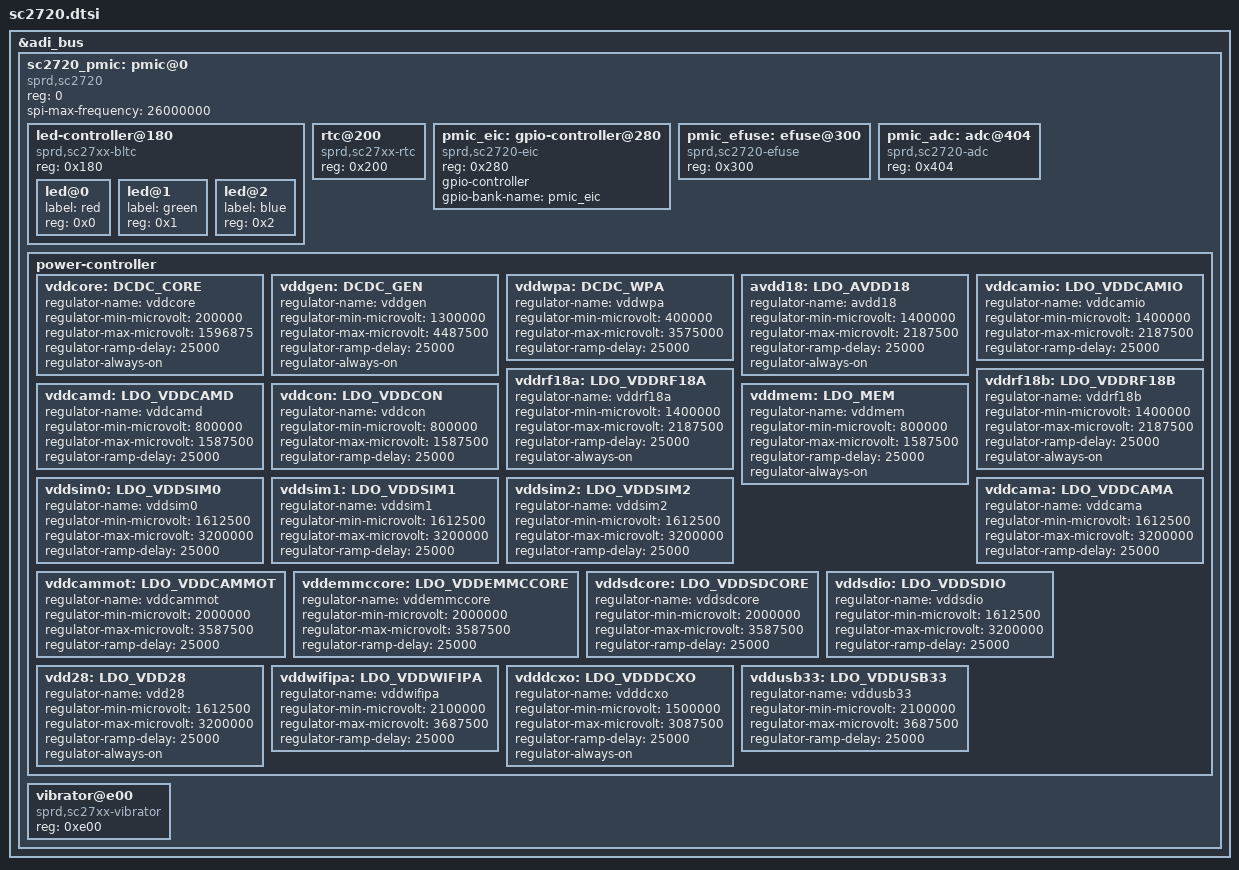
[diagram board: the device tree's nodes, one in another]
/*
 * Spreadtrum Analog Die SC2720 DTS file
 *
 * Copyright (C) 2019, Spreadtrum Communications Inc.
 *
 * This file is licensed under a dual GPLv2 or X11 license.
 */

&adi_bus {
	sc2720_pmic: pmic@0 {
		compatible = "sprd,sc2720";
		reg = <0>;
		spi-max-frequency = <26000000>;
		#address-cells = <1>;
		#size-cells = <0>;

		led-controller@180 {
			compatible = "sprd,sc27xx-bltc", "sprd,sc2721-bltc", "sprd,sc2720-bltc";
			#address-cells = <1>;
			#size-cells = <0>;
			reg = <0x180>;

			led@0 {
				label = "red";
				reg = <0x0>;
			};

			led@1 {
				label = "green";
				reg = <0x1>;
			};

			led@2 {
				label = "blue";
				reg = <0x2>;
			};
		};

		rtc@200 {
			compatible = "sprd,sc27xx-rtc";
			reg = <0x200>;
		};

		pmic_eic: gpio-controller@280 {
			compatible = "sprd,sc2720-eic", "sprd,sc2731-eic";
			reg = <0x280>;
			gpio-controller;
			gpio-bank-name = "pmic_eic";
			#gpio-cells = <2>;
		};

		pmic_efuse: efuse@300 {
			compatible = "sprd,sc2720-efuse";
			reg = <0x300>;
		};

		pmic_adc: adc@404 {
			compatible ="sprd,sc2720-adc";
			reg = <0x404>;
		};

		power-controller {
			vddcore: DCDC_CORE {
				regulator-name = "vddcore";
				regulator-min-microvolt = <200000>;
				regulator-max-microvolt = <1596875>;
				regulator-ramp-delay = <25000>;
				regulator-always-on;
			};

			vddgen: DCDC_GEN {
				regulator-name = "vddgen";
				regulator-min-microvolt = <1300000>;
				regulator-max-microvolt = <4487500>;
				regulator-ramp-delay = <25000>;
				regulator-always-on;
			};

			vddwpa: DCDC_WPA {
				regulator-name = "vddwpa";
				regulator-min-microvolt = <400000>;
				regulator-max-microvolt = <3575000>;
				regulator-ramp-delay = <25000>;
			};

			avdd18: LDO_AVDD18 {
				regulator-name = "avdd18";
				regulator-min-microvolt = <1400000>;
				regulator-max-microvolt = <2187500>;
				regulator-ramp-delay = <25000>;
				regulator-always-on;
			};

			vddcamio: LDO_VDDCAMIO {
				regulator-name = "vddcamio";
				regulator-min-microvolt = <1400000>;
				regulator-max-microvolt = <2187500>;
				regulator-ramp-delay = <25000>;
			};

			vddrf18a: LDO_VDDRF18A {
				regulator-name = "vddrf18a";
				regulator-min-microvolt = <1400000>;
				regulator-max-microvolt = <2187500>;
				regulator-ramp-delay = <25000>;
				regulator-always-on;
			};

			vddrf18b: LDO_VDDRF18B {
				regulator-name = "vddrf18b";
				regulator-min-microvolt = <1400000>;
				regulator-max-microvolt = <2187500>;
				regulator-ramp-delay = <25000>;
				regulator-always-on;
			};

			vddcamd: LDO_VDDCAMD {
				regulator-name = "vddcamd";
				regulator-min-microvolt = <800000>;
				regulator-max-microvolt = <1587500>;
				regulator-ramp-delay = <25000>;
			};

			vddcon: LDO_VDDCON {
				regulator-name = "vddcon";
				regulator-min-microvolt = <800000>;
				regulator-max-microvolt = <1587500>;
				regulator-ramp-delay = <25000>;
			};

			vddmem: LDO_MEM {
				regulator-name = "vddmem";
				regulator-min-microvolt = <800000>;
				regulator-max-microvolt = <1587500>;
				regulator-ramp-delay = <25000>;
				regulator-always-on;
			};

			vddsim0: LDO_VDDSIM0 {
				regulator-name = "vddsim0";
				regulator-min-microvolt = <1612500>;
				regulator-max-microvolt = <3200000>;
				regulator-ramp-delay = <25000>;
			};

			vddsim1: LDO_VDDSIM1 {
				regulator-name = "vddsim1";
				regulator-min-microvolt = <1612500>;
				regulator-max-microvolt = <3200000>;
				regulator-ramp-delay = <25000>;
			};

			vddsim2: LDO_VDDSIM2 {
				regulator-name = "vddsim2";
				regulator-min-microvolt = <1612500>;
				regulator-max-microvolt = <3200000>;
				regulator-ramp-delay = <25000>;
			};

			vddcama: LDO_VDDCAMA {
				regulator-name = "vddcama";
				regulator-min-microvolt = <1612500>;
				regulator-max-microvolt = <3200000>;
				regulator-ramp-delay = <25000>;
			};

			vddcammot: LDO_VDDCAMMOT {
				regulator-name = "vddcammot";
				regulator-min-microvolt = <2000000>;
				regulator-max-microvolt = <3587500>;
				regulator-ramp-delay = <25000>;
			};

			vddemmccore: LDO_VDDEMMCCORE {
				regulator-name = "vddemmccore";
				regulator-min-microvolt = <2000000>;
				regulator-max-microvolt = <3587500>;
				regulator-ramp-delay = <25000>;
			};

			vddsdcore: LDO_VDDSDCORE {
				regulator-name = "vddsdcore";
				regulator-min-microvolt = <2000000>;
				regulator-max-microvolt = <3587500>;
				regulator-ramp-delay = <25000>;
			};

			vddsdio: LDO_VDDSDIO {
				regulator-name = "vddsdio";
				regulator-min-microvolt = <1612500>;
				regulator-max-microvolt = <3200000>;
				regulator-ramp-delay = <25000>;
			};

			vdd28: LDO_VDD28 {
				regulator-name = "vdd28";
				regulator-min-microvolt = <1612500>;
				regulator-max-microvolt = <3200000>;
				regulator-ramp-delay = <25000>;
				regulator-always-on;
			};

			vddwifipa: LDO_VDDWIFIPA {
				regulator-name = "vddwifipa";
				regulator-min-microvolt = <2100000>;
				regulator-max-microvolt = <3687500>;
				regulator-ramp-delay = <25000>;
			};

			vdddcxo: LDO_VDDDCXO {
				regulator-name = "vdddcxo";
				regulator-min-microvolt = <1500000>;
				regulator-max-microvolt = <3087500>;
				regulator-ramp-delay = <25000>;
				regulator-always-on;
			};

			vddusb33: LDO_VDDUSB33 {
				regulator-name = "vddusb33";
				regulator-min-microvolt = <2100000>;
				regulator-max-microvolt = <3687500>;
				regulator-ramp-delay = <25000>;
			};
		};

		vibrator@e00 {
			compatible = "sprd,sc27xx-vibrator", "sprd,sc2721-vibrator", "sprd,sc2720-vibrator";
			reg = <0xe00>;
		};
	};
};
